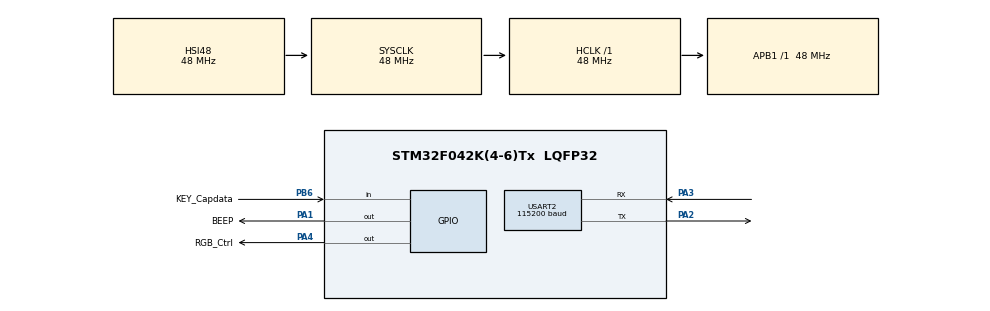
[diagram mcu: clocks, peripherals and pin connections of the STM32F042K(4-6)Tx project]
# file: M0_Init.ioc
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Dma.Request0=USART2_RX
Dma.Request1=USART2_TX
Dma.USART2_RX.0.Direction=DMA_PERIPH_TO_MEMORY
Dma.USART2_RX.0.Instance=DMA1_Channel5
Dma.USART2_RX.0.MemDataAlignment=DMA_MDATAALIGN_BYTE
Dma.USART2_RX.0.MemInc=DMA_MINC_ENABLE
Dma.USART2_RX.0.Mode=DMA_CIRCULAR
Dma.USART2_RX.0.PeriphDataAlignment=DMA_PDATAALIGN_BYTE
Dma.USART2_RX.0.PeriphInc=DMA_PINC_DISABLE
Dma.USART2_RX.0.Priority=DMA_PRIORITY_HIGH
Dma.USART2_TX.1.Direction=DMA_MEMORY_TO_PERIPH
Dma.USART2_TX.1.Instance=DMA1_Channel4
Dma.USART2_TX.1.MemDataAlignment=DMA_MDATAALIGN_BYTE
Dma.USART2_TX.1.MemInc=DMA_MINC_ENABLE
Dma.USART2_TX.1.Mode=DMA_NORMAL
Dma.USART2_TX.1.PeriphDataAlignment=DMA_PDATAALIGN_BYTE
Dma.USART2_TX.1.PeriphInc=DMA_PINC_DISABLE
Dma.USART2_TX.1.Priority=DMA_PRIORITY_HIGH
Mcu.Family=STM32F0
Mcu.Name=STM32F042K(4-6)Tx
Mcu.Package=LQFP32
NVIC.DMA1_Channel4_5_IRQn=true\:3\:0\:true\:false\:true\:false\:true\:true
NVIC.TIM1_BRK_UP_TRG_COM_IRQn=true\:3\:0\:false\:false\:true\:false\:true\:true
NVIC.USART2_IRQn=true\:3\:0\:true\:false\:true\:true\:true\:true
NVIC.TimeBase=TIM1_BRK_UP_TRG_COM_IRQn
NVIC.TimeBaseIP=TIM1
PA1.GPIO_Label=BEEP
PA1.GPIO_ModeDefaultOutputPP=GPIO_MODE_OUTPUT_PP
PA1.GPIO_PuPd=GPIO_PULLUP
PA1.GPIO_Speed=GPIO_SPEED_FREQ_MEDIUM
PA1.PinState=GPIO_PIN_SET
PA1.Signal=GPIO_Output
PA13.Mode=Serial_Wire
PA13.Signal=SYS_SWDIO
PA14.Mode=Serial_Wire
PA14.Signal=SYS_SWCLK
PA2.Mode=Asynchronous
PA2.Signal=USART2_TX
PA3.Mode=Asynchronous
PA3.Signal=USART2_RX
PA4.GPIO_Label=RGB_Ctrl
PA4.Signal=GPIO_Output
PB6.GPIO_Label=KEY_Capdata
PB6.GPIO_PuPd=GPIO_PULLUP
PB6.Signal=GPIO_Input
PF0-OSC_IN.Mode=HSE-External-Oscillator
PF0-OSC_IN.Signal=RCC_OSC_IN
PF1-OSC_OUT.Mode=HSE-External-Oscillator
PF1-OSC_OUT.Signal=RCC_OSC_OUT
ProjectManager.HeapSize=0x0
ProjectManager.StackSize=0x400
ProjectManager.TargetToolchain=CMake
RCC.AHBFreq_Value=48000000
RCC.APB1Freq_Value=48000000
RCC.APB1TimFreq_Value=48000000
RCC.HCLKFreq_Value=48000000
RCC.SYSCLKFreq_VALUE=48000000
RCC.SYSCLKSource=RCC_SYSCLKSOURCE_HSI48
USART2.BaudRate=115200
USART2.VirtualMode-Asynchronous=VM_ASYNC
VP_SYS_VS_tim1.Mode=TIM1
board=custom

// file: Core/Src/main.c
/* USER CODE BEGIN Header */
/**
  ******************************************************************************
  * @file           : main.c
  * @brief          : Main program body
  ******************************************************************************
  * @attention
  *
  * Copyright (c) 2026 STMicroelectronics.
  * All rights reserved.
  *
  * This software is licensed under terms that can be found in the LICENSE file
  * in the root directory of this software component.
  * If no LICENSE file comes with this software, it is provided AS-IS.
  *
  ******************************************************************************
  */
/* USER CODE END Header */
#include "main.h"
#include "dma.h"
#include "usart.h"
#include "gpio.h"

/* USER CODE BEGIN Includes */
#include "FreeRTOS.h"
#include "task.h"
#include "task_manager.h"
/* USER CODE END Includes */

void SystemClock_Config(void);

int main(void)
{

  /* MCU Configuration--------------------------------------------------------*/

  /* Reset of all peripherals, Initializes the Flash interface and the Systick. */
  HAL_Init();

  /* Configure the system clock */
  SystemClock_Config();

  /* Initialize all configured peripherals */
  MX_GPIO_Init();
  MX_DMA_Init();
  MX_USART2_UART_Init();
  /* USER CODE BEGIN 2 */

  /* USART2由UART BSP通过DMA独占，禁止在此使用printf或阻塞式HAL UART收发。 */
  /*
   * 统一创建所有应用任务。任务创建失败通常表示 FreeRTOS heap 不足，
   * 此时不允许启动一个缺少关键任务的系统。
   */
  task_status_t task_status = task_manager_init();
  if (TASK_OK != task_status)
  {
    /* 日志预留：记录应用任务初始化失败及task_status。 */
    Error_Handler();
  }

  /*
   * 启动 FreeRTOS 调度器。正常情况下该函数永不返回；若返回，说明空闲
   * 任务创建失败或内核启动异常，必须进入 Error_Handler() 保留现场。
   */
  vTaskStartScheduler();
  Error_Handler();

  /* USER CODE END 2 */

  /* Infinite loop */
  while (1)
  {

  }
}

void SystemClock_Config(void)
{
  RCC_OscInitTypeDef RCC_OscInitStruct = {0};
  RCC_ClkInitTypeDef RCC_ClkInitStruct = {0};

  /** Initializes the RCC Oscillators according to the specified parameters
  * in the RCC_OscInitTypeDef structure.
  */
  RCC_OscInitStruct.OscillatorType = RCC_OSCILLATORTYPE_HSI48;
  RCC_OscInitStruct.HSI48State = RCC_HSI48_ON;
  RCC_OscInitStruct.PLL.PLLState = RCC_PLL_NONE;
  if (HAL_RCC_OscConfig(&RCC_OscInitStruct) != HAL_OK)
  {
    Error_Handler();
  }

  /** Initializes the CPU, AHB and APB buses clocks
  */
  RCC_ClkInitStruct.ClockType = RCC_CLOCKTYPE_HCLK|RCC_CLOCKTYPE_SYSCLK
                              |RCC_CLOCKTYPE_PCLK1;
  RCC_ClkInitStruct.SYSCLKSource = RCC_SYSCLKSOURCE_HSI48;
  RCC_ClkInitStruct.AHBCLKDivider = RCC_SYSCLK_DIV1;
  RCC_ClkInitStruct.APB1CLKDivider = RCC_HCLK_DIV1;

  if (HAL_RCC_ClockConfig(&RCC_ClkInitStruct, FLASH_LATENCY_1) != HAL_OK)
  {
    Error_Handler();
  }
}

void HAL_TIM_PeriodElapsedCallback(TIM_HandleTypeDef *htim)
{
  if (htim->Instance == TIM1)
  {
    HAL_IncTick();
  }
}

void Error_Handler(void)
{
  __disable_irq();
  while (1)
  {
  }
}
